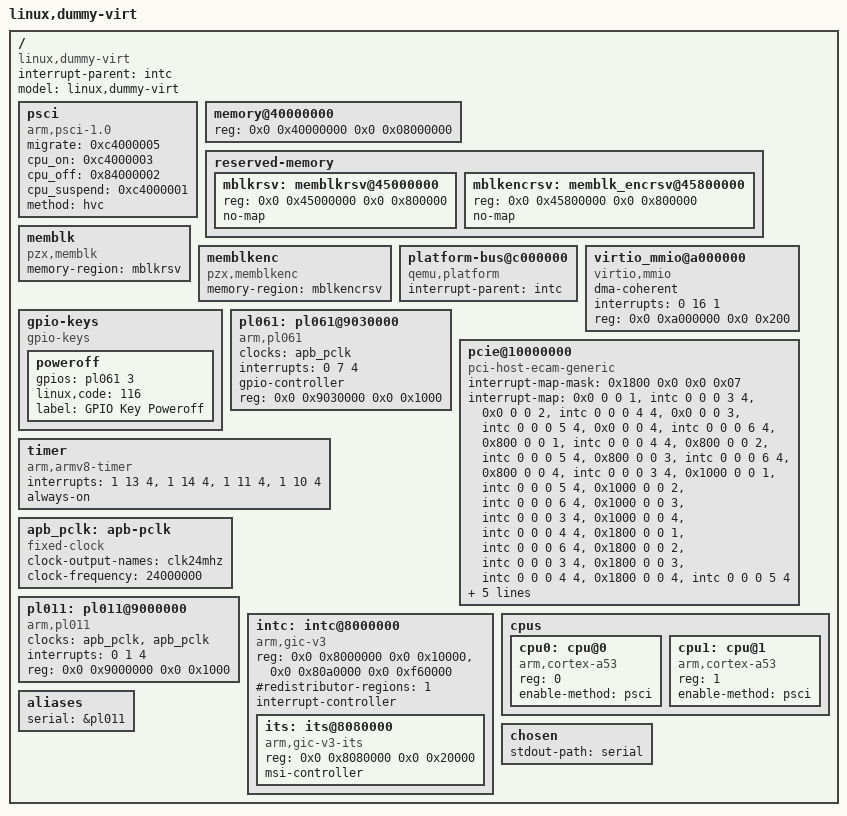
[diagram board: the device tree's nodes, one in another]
/dts-v1/;

//#include <dt-bindings/interrupt-controller/irq.h>
//#include <dt-bindings/interrupt-controller/arm-gic.h>

/ {
	interrupt-parent = <&intc>;
	model = "linux,dummy-virt";
	#size-cells = <2>;
	#address-cells = <2>;
	compatible = "linux,dummy-virt";

	psci {
		migrate = <0xc4000005>;
		cpu_on = <0xc4000003>;
		cpu_off = <0x84000002>;
		cpu_suspend = <0xc4000001>;
		method = "hvc";
		compatible = "arm,psci-1.0", "arm,psci-0.2", "arm,psci";
	};

	memory@40000000 {
		reg = <0x0 0x40000000 0x0 0x08000000>;
		device_type = "memory";
	};

	reserved-memory {
		#address-cells = <2>;
		#size-cells = <2>;
		ranges;
/*
		optee_core@47000000 {
			reg = <0x0 0x47000000 0x0 0xf00000>;
			no-map;
		};
		optee_shm@47f00000 {
			reg = <0x0 0x47f00000 0x0 0x100000>;
			no-map;
		};
*/
		mblkrsv: memblkrsv@45000000 {
			reg = <0x0 0x45000000 0x0 0x800000>;
			no-map;
		};

		mblkencrsv: memblk_encrsv@45800000 {
			reg = <0x0 0x45800000 0x0 0x800000>;
			no-map;
		};
	};

	memblk {
		compatible = "pzx,memblk";
		memory-region = <&mblkrsv>;
	};

	memblkenc {
		compatible = "pzx,memblkenc";
		memory-region = <&mblkencrsv>;
	};
/*
	firmware {
		optee {
			//interrupts = <GIC_SPI 187 IRQ_TYPE_EDGE_RISING>;
			interrupts = <0 187 1>;
			method = "smc";
			compatible = "linaro,optee-tz";
		};
	};
*/
	platform-bus@c000000 {
		interrupt-parent = <&intc>;
		ranges = <0x0 0x0 0xc000000 0x2000000>;
		#address-cells = <1>;
		#size-cells = <1>;
		compatible = "qemu,platform", "simple-bus";
	};

	virtio_mmio@a000000 {
		dma-coherent;
		//interrupts = <GIC_SPI 16 IRQ_TYPE_EDGE_RISING>;
		interrupts = <0 16 1>;
		reg = <0x0 0xa000000 0x0 0x200>;
		compatible = "virtio,mmio";
	};

	gpio-keys {
		compatible = "gpio-keys";

		poweroff {
			gpios = <&pl061 3 0>;
			linux,code = <116>;
			label = "GPIO Key Poweroff";
		};
	};

	pl061: pl061@9030000 {
		clock-names = "apb_pclk";
		clocks = <&apb_pclk>;
		//interrupts = <GIC_SPI 7 IRQ_TYPE_LEVEL_HIGH>;
		interrupts = <0 7 4>;
		gpio-controller;
		#gpio-cells = <2>;
		compatible = "arm,pl061", "arm,primecell";
		reg = <0x0 0x9030000 0x0 0x1000>;
	};

	pcie@10000000 {
		interrupt-map-mask = <0x1800 0x0 0x0 0x07>;
/*
		interrupt-map = <0x0 0 0 1 &intc 0 0 GIC_SPI 3 IRQ_TYPE_LEVEL_HIGH>,
			<0x0 0 0 2 &intc 0 0 GIC_SPI 4 IRQ_TYPE_LEVEL_HIGH>,
			<0x0 0 0 3 &intc 0 0 GIC_SPI 5 IRQ_TYPE_LEVEL_HIGH>,
			<0x0 0 0 4 &intc 0 0 GIC_SPI 6 IRQ_TYPE_LEVEL_HIGH>,
			<0x800 0 0 1 &intc 0 0 GIC_SPI 4 IRQ_TYPE_LEVEL_HIGH>,
			<0x800 0 0 2 &intc 0 0 GIC_SPI 5 IRQ_TYPE_LEVEL_HIGH>,
			<0x800 0 0 3 &intc 0 0 GIC_SPI 6 IRQ_TYPE_LEVEL_HIGH>,
			<0x800 0 0 4 &intc 0 0 GIC_SPI 3 IRQ_TYPE_LEVEL_HIGH>,
			<0x1000 0 0 1 &intc 0 0 GIC_SPI 5 IRQ_TYPE_LEVEL_HIGH>,
			<0x1000 0 0 2 &intc 0 0 GIC_SPI 6 IRQ_TYPE_LEVEL_HIGH>,
			<0x1000 0 0 3 &intc 0 0 GIC_SPI 3 IRQ_TYPE_LEVEL_HIGH>,
			<0x1000 0 0 4 &intc 0 0 GIC_SPI 4 IRQ_TYPE_LEVEL_HIGH>,
			<0x1800 0 0 1 &intc 0 0 GIC_SPI 6 IRQ_TYPE_LEVEL_HIGH>,
			<0x1800 0 0 2 &intc 0 0 GIC_SPI 3 IRQ_TYPE_LEVEL_HIGH>,
			<0x1800 0 0 3 &intc 0 0 GIC_SPI 4 IRQ_TYPE_LEVEL_HIGH>,
			<0x1800 0 0 4 &intc 0 0 GIC_SPI 5 IRQ_TYPE_LEVEL_HIGH>;
*/
		interrupt-map = <0x0 0 0 1 &intc 0 0 0 3 4>,
			<0x0 0 0 2 &intc 0 0 0 4 4>,
			<0x0 0 0 3 &intc 0 0 0 5 4>,
			<0x0 0 0 4 &intc 0 0 0 6 4>,
			<0x800 0 0 1 &intc 0 0 0 4 4>,
			<0x800 0 0 2 &intc 0 0 0 5 4>,
			<0x800 0 0 3 &intc 0 0 0 6 4>,
			<0x800 0 0 4 &intc 0 0 0 3 4>,
			<0x1000 0 0 1 &intc 0 0 0 5 4>,
			<0x1000 0 0 2 &intc 0 0 0 6 4>,
			<0x1000 0 0 3 &intc 0 0 0 3 4>,
			<0x1000 0 0 4 &intc 0 0 0 4 4>,
			<0x1800 0 0 1 &intc 0 0 0 6 4>,
			<0x1800 0 0 2 &intc 0 0 0 3 4>,
			<0x1800 0 0 3 &intc 0 0 0 4 4>,
			<0x1800 0 0 4 &intc 0 0 0 5 4>;
		#interrupt-cells = <1>;
		ranges = <0x1000000 0x0 0x0 0x0 0x3eff0000 0x0 0x10000
			0x2000000 0x0 0x10000000 0x0 0x10000000 0x0 0x2eff0000
			0x3000000 0x80 0x0 0x80 0x0 0x80 0x0>;
		reg = <0x40 0x10000000 0x0 0x10000000>;
		msi-map = <0x0 &its 0x0 0x10000>;
		dma-coherent;
		bus-range = <0x0 0xff>;
		linux,pci-domain = <0>;
		#size-cells = <2>;
		#address-cells = <3>;
		device_type = "pci";
		compatible = "pci-host-ecam-generic";
	};

	timer {
/*
		interrupts = <GIC_PPI 13 IRQ_TYPE_LEVEL_HIGH>,
			<GIC_PPI 14 IRQ_TYPE_LEVEL_HIGH>,
			<GIC_PPI 11 IRQ_TYPE_LEVEL_HIGH>,
			<GIC_PPI 10 IRQ_TYPE_LEVEL_HIGH>;
*/
		interrupts = <1 13 4>,
			<1 14 4>,
			<1 11 4>,
			<1 10 4>;
		always-on;
		compatible = "arm,armv8-timer", "arm,armv7-timer";
	};

	apb_pclk: apb-pclk {
		clock-output-names = "clk24mhz";
		clock-frequency = <24000000>;
		#clock-cells = <0>;
		compatible = "fixed-clock";
	};

	pl011: pl011@9000000 {
		clock-names = "uartclk", "apb_pclk";
		clocks = <&apb_pclk>, <&apb_pclk>;
		//interrupts = <GIC_SPI 1 IRQ_TYPE_LEVEL_HIGH>;
		interrupts = <0 1 4>;
		reg = <0x0 0x9000000 0x0 0x1000>;
		compatible = "arm,pl011", "arm,primecell";
	};

	intc: intc@8000000 {
		reg = <0x0 0x8000000 0x0 0x10000>,
			<0x0 0x80a0000 0x0 0xf60000>;
		#redistributor-regions = <1>;
		compatible = "arm,gic-v3";
		ranges;
		#size-cells = <2>;
		#address-cells = <2>;
		interrupt-controller;
		#interrupt-cells = <3>;

		its: its@8080000 {
			reg = <0x0 0x8080000 0x0 0x20000>;
			#msi-cells = <1>;
			msi-controller;
			compatible = "arm,gic-v3-its";
		};
	};

	cpus {
		#size-cells = <0>;
		#address-cells = <1>;

		cpu0: cpu@0 {
			reg = <0>;
			enable-method = "psci";
			compatible = "arm,cortex-a53";
			device_type = "cpu";
		};

		cpu1: cpu@1 {
			reg = <1>;
			enable-method = "psci";
			compatible = "arm,cortex-a53";
			device_type = "cpu";
		};
	};

	aliases {
		serial = &pl011;
	};

	chosen {
		stdout-path = "serial";
	};
};
